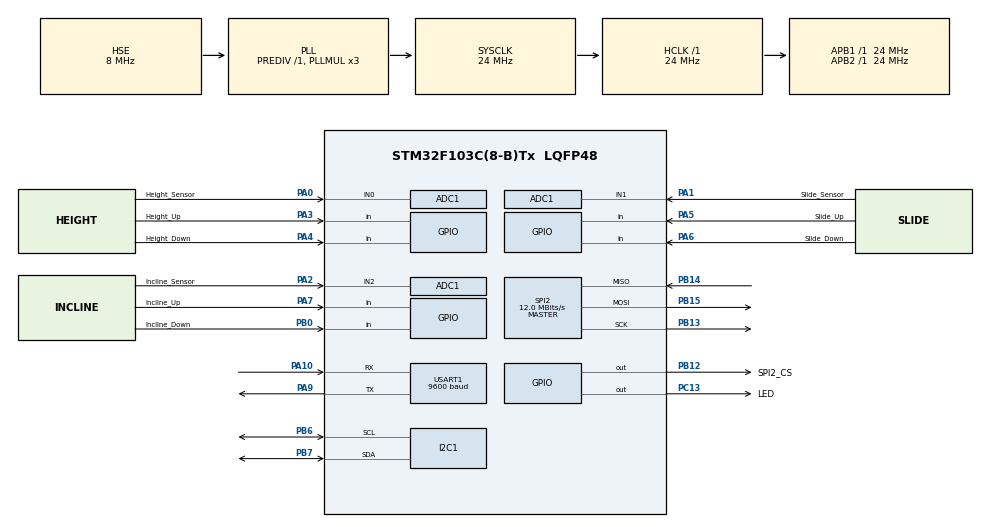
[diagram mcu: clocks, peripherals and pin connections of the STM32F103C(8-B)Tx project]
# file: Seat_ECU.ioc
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ADC1.Channel-0\#ChannelRegularConversion=ADC_CHANNEL_0
ADC1.NbrOfConversionFlag=1
ADC1.Rank-0\#ChannelRegularConversion=1
ADC1.SamplingTime-0\#ChannelRegularConversion=ADC_SAMPLETIME_1CYCLE_5
ADC1.master=1
FREERTOS.Queues01=ControlQueue,16,uint16_t,0,Dynamic,NULL,NULL;ModeQueue,16,uint16_t,0,Dynamic,NULL,NULL;ProfileQueue,16,uint16_t,0,Dynamic,NULL,NULL;FaultQueue,16,uint16_t,0,Dynamic,NULL,NULL
FREERTOS.Tasks01=ControlManager,24,128,ControlManagerTask,Default,NULL,Dynamic,NULL,NULL;ModeManager,24,128,ModeManagerTask,Default,NULL,Dynamic,NULL,NULL;ProfileManager,8,128,ProfileManagerTask,Default,NULL,Dynamic,NULL,NULL;FaultManager,8,128,FaultManagerTask,Default,NULL,Dynamic,NULL,NULL
FREERTOS.configUSE_NEWLIB_REENTRANT=0
FREERTOS.copyHeapFile=0
Mcu.Family=STM32F1
Mcu.Name=STM32F103C(8-B)Tx
Mcu.Package=LQFP48
NVIC.ADC1_2_IRQn=true\:5\:0\:false\:false\:true\:true\:true\:true\:true
NVIC.PriorityGroup=NVIC_PRIORITYGROUP_4
NVIC.TIM1_UP_IRQn=true\:15\:0\:false\:false\:true\:false\:false\:true\:true
NVIC.TimeBase=TIM1_UP_IRQn
NVIC.TimeBaseIP=TIM1
PA0-WKUP.GPIO_Label=Height_Sensor
PA0-WKUP.Signal=ADCx_IN0
PA1.GPIO_Label=Slide_Sensor
PA1.Signal=ADCx_IN1
PA10.Mode=Asynchronous
PA10.Signal=USART1_RX
PA2.GPIO_Label=Incline_Sensor
PA2.Signal=ADCx_IN2
PA3.GPIO_Label=Height_Up
PA3.GPIO_PuPd=GPIO_NOPULL
PA3.Signal=GPIO_Input
PA4.GPIO_Label=Height_Down
PA4.GPIO_PuPd=GPIO_NOPULL
PA4.Signal=GPIO_Input
PA5.GPIO_Label=Slide_Up
PA5.Signal=GPIO_Input
PA6.GPIO_Label=Slide_Down
PA6.Signal=GPIO_Input
PA7.GPIO_Label=Incline_Up
PA7.Signal=GPIO_Input
PA9.Mode=Asynchronous
PA9.Signal=USART1_TX
PB0.GPIO_Label=Incline_Down
PB0.Signal=GPIO_Input
PB12.GPIO_Label=SPI2_CS
PB12.Signal=GPIO_Output
PB13.Mode=Full_Duplex_Master
PB13.Signal=SPI2_SCK
PB14.Mode=Full_Duplex_Master
PB14.Signal=SPI2_MISO
PB15.Mode=Full_Duplex_Master
PB15.Signal=SPI2_MOSI
PB6.Mode=I2C
PB6.Signal=I2C1_SCL
PB7.Mode=I2C
PB7.Signal=I2C1_SDA
PC13-TAMPER-RTC.GPIO_Label=LED
PC13-TAMPER-RTC.Signal=GPIO_Output
PC14-OSC32_IN.Mode=LSE-External-Oscillator
PC14-OSC32_IN.Signal=RCC_OSC32_IN
PC15-OSC32_OUT.Mode=LSE-External-Oscillator
PC15-OSC32_OUT.Signal=RCC_OSC32_OUT
PD0-OSC_IN.Mode=HSE-External-Oscillator
PD0-OSC_IN.Signal=RCC_OSC_IN
PD1-OSC_OUT.Mode=HSE-External-Oscillator
PD1-OSC_OUT.Signal=RCC_OSC_OUT
ProjectManager.HeapSize=0x200
ProjectManager.StackSize=0x400
ProjectManager.TargetToolchain=STM32CubeIDE
RCC.AHBFreq_Value=24000000
RCC.APB1Freq_Value=24000000
RCC.APB1TimFreq_Value=24000000
RCC.APB2Freq_Value=24000000
RCC.APB2TimFreq_Value=24000000
RCC.HCLKFreq_Value=24000000
RCC.PLLMUL=RCC_PLL_MUL3
RCC.PLLSourceVirtual=RCC_PLLSOURCE_HSE
RCC.SYSCLKFreq_VALUE=24000000
RCC.SYSCLKSource=RCC_SYSCLKSOURCE_PLLCLK
RCC.USBFreq_Value=24000000
SH.ADCx_IN0.0=ADC1_IN0,IN0
SH.ADCx_IN1.0=ADC1_IN1,IN1
SH.ADCx_IN2.0=ADC1_IN2,IN2
SPI2.CalculateBaudRate=12.0 MBits/s
SPI2.Direction=SPI_DIRECTION_2LINES
SPI2.Mode=SPI_MODE_MASTER
SPI2.VirtualType=VM_MASTER
USART1.BaudRate=9600
USART1.VirtualMode=VM_ASYNC
VP_FREERTOS_VS_CMSIS_V2.Mode=CMSIS_V2
VP_SYS_VS_ND.Mode=No_Debug
VP_SYS_VS_tim1.Mode=TIM1
board=custom

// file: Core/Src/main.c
/* USER CODE BEGIN Header */
/**
  ******************************************************************************
  * @file           : main.c
  * @brief          : Main program body
  ******************************************************************************
  * @attention
  *
  * Copyright (c) 2025 STMicroelectronics.
  * All rights reserved.
  *
  * This software is licensed under terms that can be found in the LICENSE file
  * in the root directory of this software component.
  * If no LICENSE file comes with this software, it is provided AS-IS.
  *
  ******************************************************************************
  */
/* USER CODE END Header */
#include "main.h"
#include "cmsis_os.h"

ADC_HandleTypeDef hadc1;

I2C_HandleTypeDef hi2c1;

SPI_HandleTypeDef hspi2;

UART_HandleTypeDef huart1;

/* Definitions for ControlManager */
osThreadId_t ControlManagerHandle;
const osThreadAttr_t ControlManager_attributes = {
  .name = "ControlManager",
  .stack_size = 128 * 4,
  .priority = (osPriority_t) osPriorityNormal,
};
/* Definitions for ModeManager */
osThreadId_t ModeManagerHandle;
const osThreadAttr_t ModeManager_attributes = {
  .name = "ModeManager",
  .stack_size = 128 * 4,
  .priority = (osPriority_t) osPriorityNormal,
};
/* Definitions for ProfileManager */
osThreadId_t ProfileManagerHandle;
const osThreadAttr_t ProfileManager_attributes = {
  .name = "ProfileManager",
  .stack_size = 128 * 4,
  .priority = (osPriority_t) osPriorityLow,
};
/* Definitions for FaultManager */
osThreadId_t FaultManagerHandle;
const osThreadAttr_t FaultManager_attributes = {
  .name = "FaultManager",
  .stack_size = 128 * 4,
  .priority = (osPriority_t) osPriorityLow,
};
/* Definitions for ControlQueue */
osMessageQueueId_t ControlQueueHandle;
const osMessageQueueAttr_t ControlQueue_attributes = {
  .name = "ControlQueue"
};
/* Definitions for ModeQueue */
osMessageQueueId_t ModeQueueHandle;
const osMessageQueueAttr_t ModeQueue_attributes = {
  .name = "ModeQueue"
};
/* Definitions for ProfileQueue */
osMessageQueueId_t ProfileQueueHandle;
const osMessageQueueAttr_t ProfileQueue_attributes = {
  .name = "ProfileQueue"
};
/* Definitions for FaultQueue */
osMessageQueueId_t FaultQueueHandle;
const osMessageQueueAttr_t FaultQueue_attributes = {
  .name = "FaultQueue"
};

void SystemClock_Config(void);
static void MX_GPIO_Init(void);
static void MX_ADC1_Init(void);
static void MX_I2C1_Init(void);
static void MX_USART1_UART_Init(void);
static void MX_SPI2_Init(void);
void ControlManagerTask(void *argument);
void ModeManagerTask(void *argument);
void ProfileManagerTask(void *argument);
void FaultManagerTask(void *argument);

int main(void)
{

  /* MCU Configuration--------------------------------------------------------*/

  /* Reset of all peripherals, Initializes the Flash interface and the Systick. */
  HAL_Init();

  /* Configure the system clock */
  SystemClock_Config();

  /* Initialize all configured peripherals */
  MX_GPIO_Init();
  MX_ADC1_Init();
  MX_I2C1_Init();
  MX_USART1_UART_Init();
  MX_SPI2_Init();
  /* USER CODE BEGIN 2 */
  HAL_GPIO_WritePin(GPIOB, GPIO_PIN_12, GPIO_PIN_RESET);

  /* USER CODE END 2 */

  /* Init scheduler */
  osKernelInitialize();

  /* Create the queue(s) */
  /* creation of ControlQueue */
  ControlQueueHandle = osMessageQueueNew (16, sizeof(uint16_t), &ControlQueue_attributes);

  /* creation of ModeQueue */
  ModeQueueHandle = osMessageQueueNew (16, sizeof(uint16_t), &ModeQueue_attributes);

  /* creation of ProfileQueue */
  ProfileQueueHandle = osMessageQueueNew (16, sizeof(uint16_t), &ProfileQueue_attributes);

  /* creation of FaultQueue */
  FaultQueueHandle = osMessageQueueNew (16, sizeof(uint16_t), &FaultQueue_attributes);

  /* Create the thread(s) */
  /* creation of ControlManager */
  ControlManagerHandle = osThreadNew(ControlManagerTask, NULL, &ControlManager_attributes);

  /* creation of ModeManager */
  ModeManagerHandle = osThreadNew(ModeManagerTask, NULL, &ModeManager_attributes);

  /* creation of ProfileManager */
  ProfileManagerHandle = osThreadNew(ProfileManagerTask, NULL, &ProfileManager_attributes);

  /* creation of FaultManager */
  FaultManagerHandle = osThreadNew(FaultManagerTask, NULL, &FaultManager_attributes);

  /* Start scheduler */
  osKernelStart();

  /* We should never get here as control is now taken by the scheduler */

  /* Infinite loop */
  while (1)
  {

  }
}

void SystemClock_Config(void)
{
  RCC_OscInitTypeDef RCC_OscInitStruct = {0};
  RCC_ClkInitTypeDef RCC_ClkInitStruct = {0};
  RCC_PeriphCLKInitTypeDef PeriphClkInit = {0};

  /** Initializes the RCC Oscillators according to the specified parameters
  * in the RCC_OscInitTypeDef structure.
  */
  RCC_OscInitStruct.OscillatorType = RCC_OSCILLATORTYPE_HSE;
  RCC_OscInitStruct.HSEState = RCC_HSE_ON;
  RCC_OscInitStruct.HSEPredivValue = RCC_HSE_PREDIV_DIV1;
  RCC_OscInitStruct.HSIState = RCC_HSI_ON;
  RCC_OscInitStruct.PLL.PLLState = RCC_PLL_ON;
  RCC_OscInitStruct.PLL.PLLSource = RCC_PLLSOURCE_HSE;
  RCC_OscInitStruct.PLL.PLLMUL = RCC_PLL_MUL3;
  if (HAL_RCC_OscConfig(&RCC_OscInitStruct) != HAL_OK)
  {
    Error_Handler();
  }

  /** Initializes the CPU, AHB and APB buses clocks
  */
  RCC_ClkInitStruct.ClockType = RCC_CLOCKTYPE_HCLK|RCC_CLOCKTYPE_SYSCLK
                              |RCC_CLOCKTYPE_PCLK1|RCC_CLOCKTYPE_PCLK2;
  RCC_ClkInitStruct.SYSCLKSource = RCC_SYSCLKSOURCE_PLLCLK;
  RCC_ClkInitStruct.AHBCLKDivider = RCC_SYSCLK_DIV1;
  RCC_ClkInitStruct.APB1CLKDivider = RCC_HCLK_DIV1;
  RCC_ClkInitStruct.APB2CLKDivider = RCC_HCLK_DIV1;

  if (HAL_RCC_ClockConfig(&RCC_ClkInitStruct, FLASH_LATENCY_0) != HAL_OK)
  {
    Error_Handler();
  }
  PeriphClkInit.PeriphClockSelection = RCC_PERIPHCLK_ADC;
  PeriphClkInit.AdcClockSelection = RCC_ADCPCLK2_DIV2;
  if (HAL_RCCEx_PeriphCLKConfig(&PeriphClkInit) != HAL_OK)
  {
    Error_Handler();
  }
}

static void MX_ADC1_Init(void)
{

  ADC_ChannelConfTypeDef sConfig = {0};

  /** Common config
  */
  hadc1.Instance = ADC1;
  hadc1.Init.ScanConvMode = ADC_SCAN_DISABLE;
  hadc1.Init.ContinuousConvMode = DISABLE;
  hadc1.Init.DiscontinuousConvMode = DISABLE;
  hadc1.Init.ExternalTrigConv = ADC_SOFTWARE_START;
  hadc1.Init.DataAlign = ADC_DATAALIGN_RIGHT;
  hadc1.Init.NbrOfConversion = 1;
  if (HAL_ADC_Init(&hadc1) != HAL_OK)
  {
    Error_Handler();
  }

  /** Configure Regular Channel
  */
  sConfig.Channel = ADC_CHANNEL_0;
  sConfig.Rank = ADC_REGULAR_RANK_1;
  sConfig.SamplingTime = ADC_SAMPLETIME_1CYCLE_5;
  if (HAL_ADC_ConfigChannel(&hadc1, &sConfig) != HAL_OK)
  {
    Error_Handler();
  }

}

static void MX_I2C1_Init(void)
{

  hi2c1.Instance = I2C1;
  hi2c1.Init.ClockSpeed = 100000;
  hi2c1.Init.DutyCycle = I2C_DUTYCYCLE_2;
  hi2c1.Init.OwnAddress1 = 0;
  hi2c1.Init.AddressingMode = I2C_ADDRESSINGMODE_7BIT;
  hi2c1.Init.DualAddressMode = I2C_DUALADDRESS_DISABLE;
  hi2c1.Init.OwnAddress2 = 0;
  hi2c1.Init.GeneralCallMode = I2C_GENERALCALL_DISABLE;
  hi2c1.Init.NoStretchMode = I2C_NOSTRETCH_DISABLE;
  if (HAL_I2C_Init(&hi2c1) != HAL_OK)
  {
    Error_Handler();
  }

}

static void MX_SPI2_Init(void)
{

  /* SPI2 parameter configuration*/
  hspi2.Instance = SPI2;
  hspi2.Init.Mode = SPI_MODE_MASTER;
  hspi2.Init.Direction = SPI_DIRECTION_2LINES;
  hspi2.Init.DataSize = SPI_DATASIZE_8BIT;
  hspi2.Init.CLKPolarity = SPI_POLARITY_LOW;
  hspi2.Init.CLKPhase = SPI_PHASE_1EDGE;
  hspi2.Init.NSS = SPI_NSS_SOFT;
  hspi2.Init.BaudRatePrescaler = SPI_BAUDRATEPRESCALER_2;
  hspi2.Init.FirstBit = SPI_FIRSTBIT_MSB;
  hspi2.Init.TIMode = SPI_TIMODE_DISABLE;
  hspi2.Init.CRCCalculation = SPI_CRCCALCULATION_DISABLE;
  hspi2.Init.CRCPolynomial = 10;
  if (HAL_SPI_Init(&hspi2) != HAL_OK)
  {
    Error_Handler();
  }

}

static void MX_USART1_UART_Init(void)
{

  huart1.Instance = USART1;
  huart1.Init.BaudRate = 9600;
  huart1.Init.WordLength = UART_WORDLENGTH_8B;
  huart1.Init.StopBits = UART_STOPBITS_1;
  huart1.Init.Parity = UART_PARITY_NONE;
  huart1.Init.Mode = UART_MODE_TX_RX;
  huart1.Init.HwFlowCtl = UART_HWCONTROL_NONE;
  huart1.Init.OverSampling = UART_OVERSAMPLING_16;
  if (HAL_UART_Init(&huart1) != HAL_OK)
  {
    Error_Handler();
  }

}

static void MX_GPIO_Init(void)
{
  GPIO_InitTypeDef GPIO_InitStruct = {0};

  /* GPIO Ports Clock Enable */
  __HAL_RCC_GPIOC_CLK_ENABLE();
  __HAL_RCC_GPIOD_CLK_ENABLE();
  __HAL_RCC_GPIOA_CLK_ENABLE();
  __HAL_RCC_GPIOB_CLK_ENABLE();

  /*Configure GPIO pin Output Level */
  HAL_GPIO_WritePin(LED_GPIO_Port, LED_Pin, GPIO_PIN_RESET);

  /*Configure GPIO pin Output Level */
  HAL_GPIO_WritePin(SPI2_CS_GPIO_Port, SPI2_CS_Pin, GPIO_PIN_RESET);

  /*Configure GPIO pin : LED_Pin */
  GPIO_InitStruct.Pin = LED_Pin;
  GPIO_InitStruct.Mode = GPIO_MODE_OUTPUT_PP;
  GPIO_InitStruct.Pull = GPIO_NOPULL;
  GPIO_InitStruct.Speed = GPIO_SPEED_FREQ_LOW;
  HAL_GPIO_Init(LED_GPIO_Port, &GPIO_InitStruct);

  /*Configure GPIO pins : Height_Up_Pin Height_Down_Pin Slide_Up_Pin Slide_Down_Pin
                           Incline_Up_Pin */
  GPIO_InitStruct.Pin = Height_Up_Pin|Height_Down_Pin|Slide_Up_Pin|Slide_Down_Pin
                          |Incline_Up_Pin;
  GPIO_InitStruct.Mode = GPIO_MODE_INPUT;
  GPIO_InitStruct.Pull = GPIO_NOPULL;
  HAL_GPIO_Init(GPIOA, &GPIO_InitStruct);

  /*Configure GPIO pin : Incline_Down_Pin */
  GPIO_InitStruct.Pin = Incline_Down_Pin;
  GPIO_InitStruct.Mode = GPIO_MODE_INPUT;
  GPIO_InitStruct.Pull = GPIO_NOPULL;
  HAL_GPIO_Init(Incline_Down_GPIO_Port, &GPIO_InitStruct);

  /*Configure GPIO pin : SPI2_CS_Pin */
  GPIO_InitStruct.Pin = SPI2_CS_Pin;
  GPIO_InitStruct.Mode = GPIO_MODE_OUTPUT_PP;
  GPIO_InitStruct.Pull = GPIO_NOPULL;
  GPIO_InitStruct.Speed = GPIO_SPEED_FREQ_LOW;
  HAL_GPIO_Init(SPI2_CS_GPIO_Port, &GPIO_InitStruct);

}

void ControlManagerTask(void *argument)
{
  /* USER CODE BEGIN 5 */
  uint8_t rxData[4] = { 0 };
  uint8_t txData[4] = { "Hell" };
  /* Infinite loop */
  for(;;)
  {
//	HAL_SPI_TransmitReceive(&hspi2, txData, rxData, sizeof(txData), HAL_MAX_DELAY);
    osDelay(1);
  }
  /* USER CODE END 5 */
}

void ModeManagerTask(void *argument)
{
  /* USER CODE BEGIN ModeManagerTask */
  /* Infinite loop */
  for(;;)
  {
//	HAL_GPIO_TogglePin(GPIOC, GPIO_PIN_13);
    osDelay(500);
  }
  /* USER CODE END ModeManagerTask */
}

void ProfileManagerTask(void *argument)
{
  for(;;)
  {
    osDelay(1);
  }
}

void FaultManagerTask(void *argument)
{
  for(;;)
  {
    osDelay(1);
  }
}

void HAL_TIM_PeriodElapsedCallback(TIM_HandleTypeDef *htim)
{
  if (htim->Instance == TIM1)
  {
    HAL_IncTick();
  }
}

void Error_Handler(void)
{
  __disable_irq();
  while (1)
  {
  }
}
